VERSION ""

NS_ :

BS_:

BU_: XXX

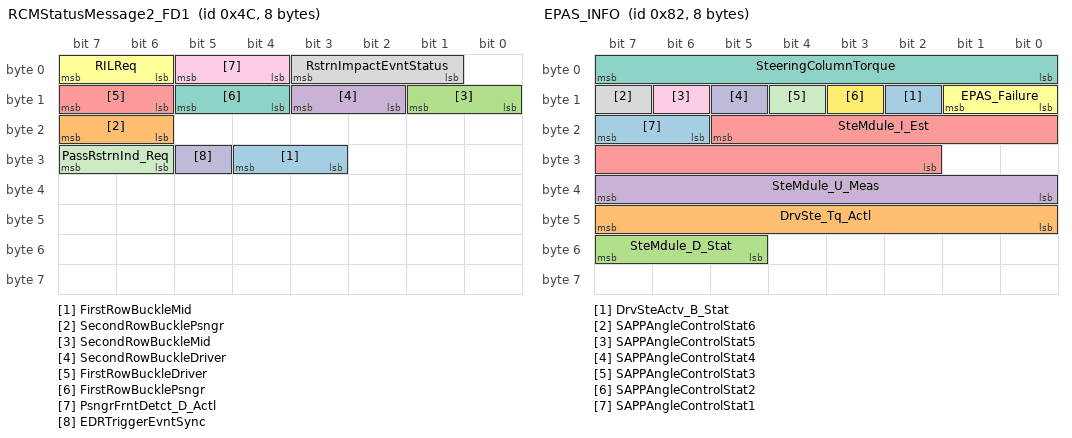
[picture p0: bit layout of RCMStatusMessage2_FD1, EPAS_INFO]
BO_ 76 RCMStatusMessage2_FD1: 8 GWM
 SG_ FirstRowBuckleMid : 28|2@0+ (1,0) [0|3] "SED"  IPMA_ADAS
 SG_ SecondRowBucklePsngr : 23|2@0+ (1,0) [0|3] "SED" Vector__XXX
 SG_ SecondRowBuckleMid : 9|2@0+ (1,0) [0|3] "SED" Vector__XXX
 SG_ SecondRowBuckleDriver : 11|2@0+ (1,0) [0|3] "SED" Vector__XXX
 SG_ FirstRowBuckleDriver : 15|2@0+ (1,0) [0|3] "SED"  CMR_DSMC,ABS_ESC,IPMA_ADAS,ECM_Diesel,PCM,PCM_HEV,TCM_DSL
 SG_ RILReq : 7|2@0+ (1,0) [0|3] "SED" Vector__XXX
 SG_ FirstRowBucklePsngr : 13|2@0+ (1,0) [0|3] "SED"  IPMA_ADAS
 SG_ RstrnImpactEvntStatus : 3|3@0+ (1,0) [0|7] "SED"  CMR_DSMC,SOBDMC_HPCM_FD1,ABS_ESC,IPMA_ADAS,ECM_Diesel,PCM,PCM_HEV,TCM_DSL
 SG_ PsngrFrntDetct_D_Actl : 5|2@0+ (1,0) [0|3] "SED" Vector__XXX
 SG_ EDRTriggerEvntSync : 29|1@0+ (1,0) [0|1] "SED"  IPMA_ADAS
 SG_ PassRstrnInd_Req : 31|2@0+ (1,0) [0|3] "SED" Vector__XXX

BO_ 130 EPAS_INFO: 8 PSCM
 SG_ DrvSteActv_B_Stat : 10|1@0+ (1,0) [0|1] "SED"  GWM,ABS_ESC
 SG_ DrvSte_Tq_Actl : 47|8@0+ (0.0625,-8) [-8|7.8125] "Nm"  GWM,ABS_ESC
 SG_ SteMdule_D_Stat : 55|3@0+ (1,0) [0|7] "SED"  GWM
 SG_ SteMdule_U_Meas : 39|8@0+ (0.05,6) [6|18.7] "Volts"  GWM
 SG_ SteMdule_I_Est : 21|12@0+ (0.05,-64) [-64|140.7] "Amps"  GWM
 SG_ EPAS_Failure : 9|2@0+ (1,0) [0|3] "SED"  IPMA_ADAS,GWM
 SG_ SteeringColumnTorque : 7|8@0+ (0.0625,-8) [-8|7.8125] "Nm"  GWM,IPMA_ADAS,ABS_ESC
 SG_ SAPPAngleControlStat6 : 15|1@0+ (1,0) [0|1] "SED"  GWM,IPMA_ADAS
 SG_ SAPPAngleControlStat5 : 14|1@0+ (1,0) [0|1] "SED"  GWM,IPMA_ADAS
 SG_ SAPPAngleControlStat4 : 13|1@0+ (1,0) [0|1] "SED"  GWM,IPMA_ADAS
 SG_ SAPPAngleControlStat3 : 12|1@0+ (1,0) [0|1] "SED"  GWM,IPMA_ADAS
 SG_ SAPPAngleControlStat2 : 11|1@0+ (1,0) [0|1] "SED"  GWM,IPMA_ADAS
 SG_ SAPPAngleControlStat1 : 23|2@0+ (1,0) [0|3] "SED"  GWM,IPMA_ADAS

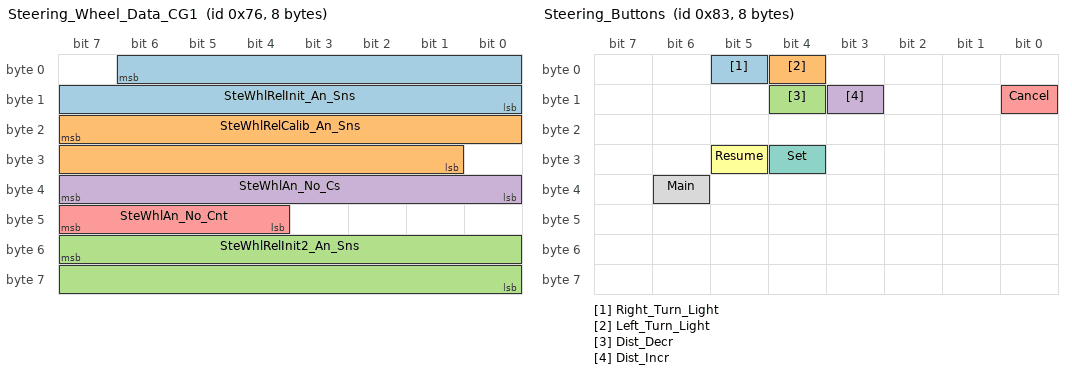
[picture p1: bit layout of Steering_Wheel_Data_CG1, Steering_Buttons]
BO_ 118 Steering_Wheel_Data_CG1: 8 XXX
 SG_ SteWhlRelInit_An_Sns : 6|15@0+ (0.1,-1600.0) [0|0] "deg" XXX
 SG_ SteWhlRelCalib_An_Sns : 23|15@0+ (0.1,-1600.0) [0|0] "deg" XXX
 SG_ SteWhlRelInit2_An_Sns : 55|16@0+ (0.1,-3200.0) [0|0] "deg" XXX
 SG_ SteWhlAn_No_Cs : 39|8@0+ (1,0) [0|0] "" XXX
 SG_ SteWhlAn_No_Cnt : 47|4@0+ (1,0) [0|0] "Counts" XXX

BO_ 131 Steering_Buttons: 8 XXX
 SG_ Right_Turn_Light : 5|1@0+ (1,0) [0|0] "" XXX
 SG_ Left_Turn_Light : 4|1@0+ (1,0) [0|0] "" XXX
 SG_ Dist_Decr : 12|1@0+ (1,0) [0|0] "" XXX
 SG_ Dist_Incr : 11|1@0+ (1,0) [0|0] "" XXX
 SG_ Cancel : 8|1@0+ (1,0) [0|0] "" XXX
 SG_ Resume : 29|1@0+ (1,0) [0|0] "" XXX
 SG_ Set : 28|1@0+ (1,0) [0|0] "" XXX
 SG_ Main : 38|1@0+ (1,0) [0|0] "" XXX

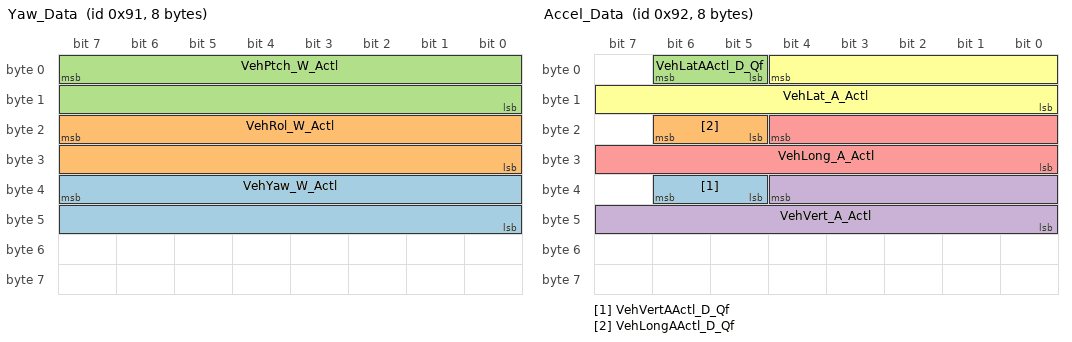
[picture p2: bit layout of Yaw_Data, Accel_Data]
BO_ 145 Yaw_Data: 8 XXX
 SG_ VehYaw_W_Actl : 39|16@0+ (0.0002,-6.5) [0|0] "rad/s" XXX
 SG_ VehRol_W_Actl : 23|16@0+ (0.0002,-6.5) [0|0] "rad/s" XXX
 SG_ VehPtch_W_Actl : 7|16@0+ (0.0002,-6.5) [0|0] "rad/s" XXX

BO_ 146 Accel_Data: 8 XXX
 SG_ VehVertAActl_D_Qf : 38|2@0+ (1,0) [0|0] "" XXX
 SG_ VehLongAActl_D_Qf : 22|2@0+ (1,0) [0|0] "" XXX
 SG_ VehLatAActl_D_Qf : 6|2@0+ (1,0) [0|0] "" XXX
 SG_ VehVert_A_Actl : 36|13@0+ (0.01,-40.0) [0|0] "m/s^2" XXX
 SG_ VehLong_A_Actl : 20|13@0+ (0.01,-40.0) [0|0] "m/s^2" XXX
 SG_ VehLat_A_Actl : 4|13@0+ (0.01,-40.0) [0|0] "m/s^2" XXX

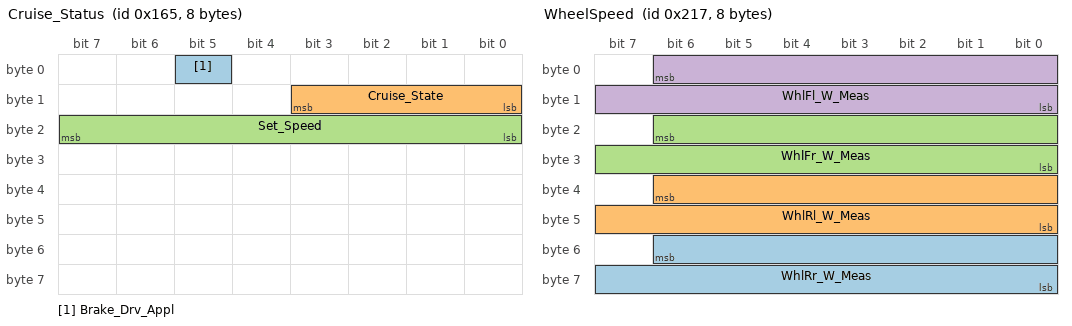
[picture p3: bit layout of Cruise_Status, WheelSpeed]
BO_ 357 Cruise_Status: 8 XXX
 SG_ Brake_Drv_Appl : 5|1@0+ (1,0) [0|0] "" XXX
 SG_ Cruise_State : 11|4@0+ (1,0) [0|0] "" XXX
 SG_ Set_Speed : 23|8@0+ (1,0) [0|0] "" XXX

BO_ 516 EngineData_14: 8 XXX
 SG_ ApedPosScal_Pc_Actl : 1|10@0+ (0.1,0) [0|0] "%" XXX

BO_ 535 WheelSpeed: 8 ABS_ESC
 SG_ WhlRr_W_Meas : 54|15@0+ (0.01,0) [0|327.65] "rad/s"  VDM,IPMA_ADAS,GWM,ECM_Diesel,PCM,PCM_HEV,PSCM,TCCM,TCM_DSL
 SG_ WhlRl_W_Meas : 38|15@0+ (0.01,0) [0|327.65] "rad/s"  VDM,IPMA_ADAS,GWM,ECM_Diesel,PCM,PCM_HEV,PSCM,TCCM,TCM_DSL
 SG_ WhlFr_W_Meas : 22|15@0+ (0.01,0) [0|327.65] "rad/s"  VDM,IPMA_ADAS,GWM,ECM_Diesel,PCM,PCM_HEV,PSCM,TCCM,TCM_DSL
 SG_ WhlFl_W_Meas : 6|15@0+ (0.01,0) [0|327.65] "rad/s"  VDM,IPMA_ADAS,GWM,ECM_Diesel,PCM,PCM_HEV,PSCM,TCCM,TCM_DSL

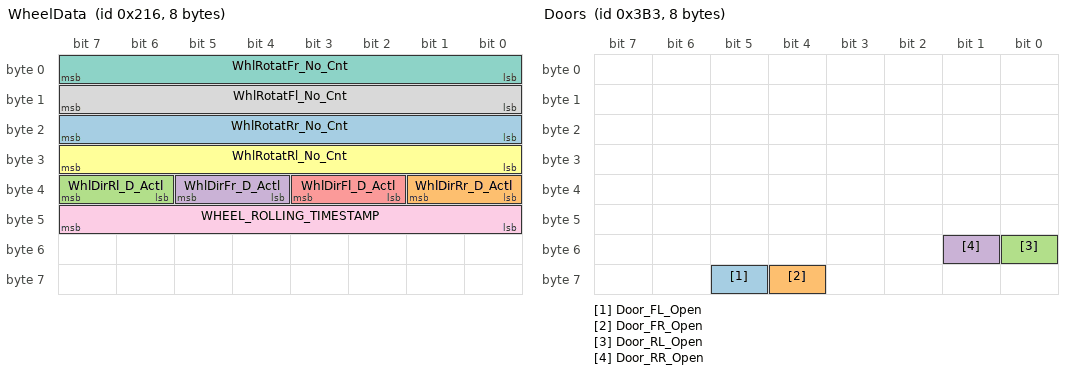
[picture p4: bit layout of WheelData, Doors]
BO_ 534 WheelData: 8 XXX
 SG_ WhlRotatRr_No_Cnt : 23|8@0+ (1,0) [0|0] "" XXX
 SG_ WhlDirRr_D_Actl : 33|2@0+ (1,0) [0|0] "" XXX
 SG_ WhlDirRl_D_Actl : 39|2@0+ (1,0) [0|0] "" XXX
 SG_ WhlDirFr_D_Actl : 37|2@0+ (1,0) [0|0] "" XXX
 SG_ WhlDirFl_D_Actl : 35|2@0+ (1,0) [0|0] "" XXX
 SG_ WhlRotatRl_No_Cnt : 31|8@0+ (1,0) [0|0] "" XXX
 SG_ WhlRotatFr_No_Cnt : 7|8@0+ (1,0) [0|0] "" XXX
 SG_ WhlRotatFl_No_Cnt : 15|8@0+ (1,0) [0|0] "" XXX
 SG_ WHEEL_ROLLING_TIMESTAMP : 47|8@0+ (1,0) [0|0] "" XXX

BO_ 947 Doors: 8 XXX
 SG_ Door_FL_Open : 61|1@0+ (1,0) [0|0] "" XXX
 SG_ Door_FR_Open : 60|1@0+ (1,0) [0|0] "" XXX
 SG_ Door_RL_Open : 48|1@0+ (1,0) [0|0] "" XXX
 SG_ Door_RR_Open : 49|1@0+ (1,0) [0|0] "" XXX

BO_ 963 BCM_to_HS_Body: 8 XXX
 SG_ Brake_Lights : 8|1@0+ (1,0) [0|0] "" XXX

BO_ 970 Lane_Keep_Assist_Control: 8 IPMA_ADAS
 SG_ Lkas_Action : 7|3@0+ (1,0) [0|7] "SED"  PSCM
 SG_ Lkas_Alert : 3|4@0+ (1,0) [0|15] "" XXX
 SG_ Lane_Curvature : 15|12@0+ (5E-006,-0.01024) [-0.01024|0.01023] "1/m"  PSCM
 SG_ Steer_Angle_Req : 19|12@0+ (0.05,-102.4) [-102.4|102.3] "mrad"  PSCM
 SG_ LkaDrvOvrrd_D_Rq : 38|2@0+ (1,0) [0|3] "SED"  PSCM
 SG_ LdwActvStats_D_Req : 4|3@0+ (1,0) [0|7] "SED"  PSCM
 SG_ LdwActvIntns_D_Req : 1|2@0+ (1,0) [0|3] "SED"  PSCM
 SG_ LaRampType_B_Req : 39|1@0+ (1,0) [0|1] "SED"  PSCM

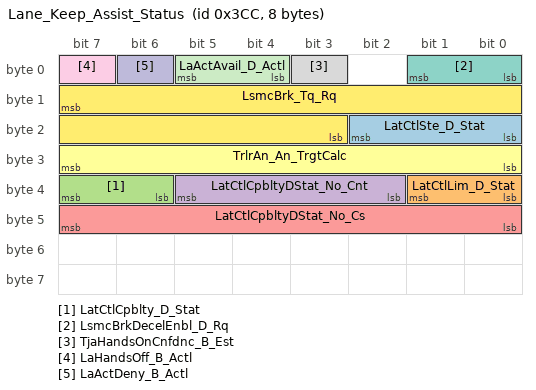
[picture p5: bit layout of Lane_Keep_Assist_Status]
BO_ 972 Lane_Keep_Assist_Status: 8 PSCM
 SG_ LatCtlSte_D_Stat : 18|3@0+ (1,0) [0|7] "SED"  IPMA_ADAS,GWM
 SG_ LatCtlLim_D_Stat : 33|2@0+ (1,0) [0|3] "SED"  IPMA_ADAS,GWM
 SG_ LatCtlCpblty_D_Stat : 39|2@0+ (1,0) [0|3] "SED"  IPMA_ADAS,GWM
 SG_ LatCtlCpbltyDStat_No_Cnt : 37|4@0+ (1,0) [0|15] "Unitless"  IPMA_ADAS,GWM
 SG_ LatCtlCpbltyDStat_No_Cs : 47|8@0+ (1,0) [0|255] "Unitless"  IPMA_ADAS,GWM
 SG_ TrlrAn_An_TrgtCalc : 31|8@0+ (1,-128) [-128|127] "degrees"  IPMA_ADAS
 SG_ LsmcBrkDecelEnbl_D_Rq : 1|2@0+ (1,0) [0|3] "SED"  ABS_ESC
 SG_ TjaHandsOnCnfdnc_B_Est : 3|1@0+ (1,0) [0|1] "SED"  IPMA_ADAS
 SG_ LaHandsOff_B_Actl : 7|1@0+ (1,0) [0|1] "SED"  IPMA_ADAS,GWM
 SG_ LaActDeny_B_Actl : 6|1@0+ (1,0) [0|1] "SED"  IPMA_ADAS,GWM
 SG_ LaActAvail_D_Actl : 5|2@0+ (1,0) [0|3] "SED"  IPMA_ADAS,GWM
 SG_ LsmcBrk_Tq_Rq : 15|13@0+ (4,0) [0|32764] "Nm"  ABS_ESC

BO_ 984 Lane_Keep_Assist_Ui: 8 IPMA_ADAS
 SG_ FeatConfigIpmaActl : 7|16@0+ (1,0) [0|65535] "Undefined"  GWM
 SG_ FeatNoIpmaActl : 23|16@0+ (1,0) [0|65535] "Number"  GWM
 SG_ PersIndexIpma_D_Actl : 39|3@0+ (1,0) [0|7] "SED"  GWM
 SG_ AhbcRampingV_D_Rq : 57|2@0+ (1,0) [0|3] "SED"  GWM
 SG_ Lines_Hud : 55|5@0+ (1,0) [0|31] "SED"  GWM
 SG_ LaDenyStats_B_Dsply : 32|1@0+ (1,0) [0|1] "SED"  GWM
 SG_ Hands_Warning_W_Chime : 50|2@0+ (1,0) [0|3] "SED"  GWM
 SG_ CamraDefog_B_Req : 36|1@0+ (1,0) [0|1] "SED"  GWM
 SG_ CamraStats_D_Dsply : 35|2@0+ (1,0) [0|3] "SED"  GWM
 SG_ DasAlrtLvl_D_Dsply : 42|3@0+ (1,0) [0|7] "SED"  GWM
 SG_ DasStats_D_Dsply : 47|2@0+ (1,0) [0|3] "SED"  GWM
 SG_ DasWarn_D_Dsply : 44|2@0+ (1,0) [0|3] "SED"  GWM
 SG_ AhbHiBeam_D_Rq : 59|2@0+ (1,0) [0|3] "SED"  GWM
 SG_ Hands_Warning : 49|1@0+ (1,0) [0|1] "SED"  GWM
 SG_ Set_Me_X30 : 63|8@0+ (1,0) [0|255] "SED"  GWM

CM_ SG_ 970 Lkas_Action "only vals 4, 5, 8, 9 seem to work. 4 and 5 are a bit smoother" ;

VAL_ 76 FirstRowBuckleMid 3 "Unknown" 2 "Unbelted" 1 "Belted" 0 "Faulty" ;
VAL_ 76 SecondRowBucklePsngr 3 "Unknown" 2 "Unbelted" 1 "Belted" 0 "Faulty" ;
VAL_ 76 SecondRowBuckleMid 3 "Unknown" 2 "Unbelted" 1 "Belted" 0 "Faulty" ;
VAL_ 76 SecondRowBuckleDriver 3 "Unknown" 2 "Unbelted" 1 "Belted" 0 "Faulty" ;
VAL_ 76 FirstRowBuckleDriver 3 "Unknown" 2 "Unbelted" 1 "Belted" 0 "Faulty" ;
VAL_ 76 RILReq 3 "Not_Used" 2 "Plant_Mode" 1 "On" 0 "Off" ;
VAL_ 76 FirstRowBucklePsngr 3 "Unknown" 2 "Unbelted" 1 "Belted" 0 "Faulty" ;
VAL_ 76 RstrnImpactEvntStatus 7 "Invalid" 6 "Not_Used_4" 5 "Threshold_2_Exceeded" 4 "Not_Used_3" 3 "Threshold_1_Exceeded" 2 "Not_Used_2" 1 "Not_Used_1" 0 "Normal" ;
VAL_ 76 PsngrFrntDetct_D_Actl 3 "Unknown" 2 "Empty" 0 "Faulty" 1 "Occupied" ;
VAL_ 76 EDRTriggerEvntSync 1 "Threshold_Exceeded" 0 "Normal" ;
VAL_ 76 PassRstrnInd_Req 3 "ABOnNotIllum_OffNotIllum" 2 "AirbagOnNot_Illum_OffIllum" 1 "AirbagOn_Illum_OffNotIllum" 0 "AirbagOn_Illum_Off_Illum" ;
VAL_ 130 TrlrHitchLamp_D_Rqst 1 "On" 0 "Off" ;
VAL_ 130 VehVTrlrAid_B_Rq 1 "Request" 0 "NoRequest" ;
VAL_ 130 DrvSteActv_B_Stat 1 "Active" 0 "Inactive" ;
VAL_ 130 DrvSte_Tq_Actl 255 "Invalid" 254 "Unknown" ;
VAL_ 130 SteMdule_D_Stat 7 "NotUsed" 6 "EPAS_Failure3" 5 "EPAS_Failure2" 4 "System_Failure" 3 "EPAS_Shutdown" 2 "Normal_Op_Full_Assist" 1 "Normal_Op_Limited_Assist" 0 "EPAS_Initialization" ;
VAL_ 130 SteMdule_U_Meas 255 "Invalid" ;
VAL_ 130 SteMdule_I_Est 4095 "Invalid" ;
VAL_ 130 EPAS_Failure 3 "SERVICE_POWER_STEERING_NOW" 2 "SERVICE_POWER_STEERING" 1 "POWER_STRG_ASSIST_FAULT" 0 "EPAS_OK_NO_MESSAGE" ;
VAL_ 130 SteeringColumnTorque 255 "Invalid" 254 "Unknown" ;
VAL_ 130 SAPPAngleControlStat6 1 "RequestedAngleNotReached" 0 "RequestedAngleCanBeReached" ;
VAL_ 130 SAPPAngleControlStat5 1 "StrgColTorqueExceed_EAROn" 0 "ExternalSigContentOKforEAC" ;
VAL_ 130 SAPPAngleControlStat4 1 "SpeedLimitExceededEAROn" 0 "ExternalSigContentOKforEAC" ;
VAL_ 130 SAPPAngleControlStat3 1 "EARactiveNoReverseEngage" 0 "ExternalSigContentOKforEAC" ;
VAL_ 130 SAPPAngleControlStat2 1 "Rel_ExtSteeringAngleReqx" 0 "NoRel_ExtSteeringAngleReqx" ;
VAL_ 130 SAPPAngleControlStat1 3 "Fault" 2 "Active" 1 "Open" 0 "Closed" ;
VAL_ 357 Cruise_State 4 "active" 3 "standby" 0 "off" ;
VAL_ 970 LkaDrvOvrrd_D_Rq 3 "Level_3" 2 "Level_2" 1 "Level_1" 0 "Level_0" ;
VAL_ 970 Lkas_Action 7 "NotUsed" 6 "LkaIncrIntervRight" 5 "LkaSupprRight" 4 "LkaStandIntervRight" 3 "LkaSupprLeft" 2 "LkaStandIntervLeft" 1 "LkaIncrIntervLeft" 0 "LkaNoInterv" ;
CM_ VAL_ 970 Lkas_Alert 15 "no_alert" 3 "high_intensity" 2 "mid_intensity" 1 "low_intensity" ;
VAL_ 970 Steer_angle_Req 4095 "Fault" ;
VAL_ 970 LaRampType_B_Req 1 "Quick" 0 "Smooth" ;
VAL_ 970 Lkas_Curvature 4095 "Fault" ;
VAL_ 970 LdwActvStats_D_Req 7 "LDW_Suppress_Right_Left" 6 "Not_Used2" 5 "LDW_Suppress_Right" 4 "LDW_Warning_Right" 3 "LDW_Suppress_Left" 2 "LDW_Warning_Left" 1 "LDW_DemoVibration" 0 "LDW_Idle" ;
VAL_ 970 LdwActvIntns_D_Req 3 "High" 2 "Medium" 1 "Low" 0 "None" ;
VAL_ 970 Lkas_Alert 15 "no_alert" 3 "high_intensity" 2 "mid_intensity" 1 "low_intensity" ;
VAL_ 972 LatCtlSte_D_Stat 7 "NotUsed3" 6 "NotUsed2" 5 "NotUsed1" 4 "Denied" 3 "RampOut" 2 "ContLatControlInProgress" 1 "Available" 0 "Unavailable" ;
VAL_ 972 LatCtlLim_D_Stat 3 "LimitWithDriverActive" 2 "LimitReached" 1 "LimitClose" 0 "LimitNotReached" ;
VAL_ 972 LatCtlCpblty_D_Stat 3 "Faulty" 2 "ExtendedModeAvailable" 1 "LimitedModeAvailable" 0 "NoModeAvailable" ;
VAL_ 972 LsmcBrkDecelEnbl_D_Rq 3 "NotUsed2" 2 "NotUsed1" 1 "On" 0 "Off" ;
VAL_ 972 TjaHandsOnCnfdnc_B_Est 1 "High_Confidence" 0 "Low_Confidence" ;
VAL_ 972 LaHandsOff_B_Actl 1 "Hands_Off" 0 "Hands_On" ;
VAL_ 972 LaActDeny_B_Actl 1 "LA_Denied" 0 "LA_Not_Denied" ;
VAL_ 972 LaActAvail_D_Actl 3 "LKA_LCA_LDW_Avail" 2 "LCA_LKA_Avail_LDW_Suppress" 1 "LCA_LKA_Suppress_LDW_Avail" 0
VAL_ 984 PersIndexIpma_D_Actl 7 "Unused_3" 6 "Unused_2" 5 "Unused_1" 4 "Vehicle" 3 "PERS_4" 2 "PERS_3" 1 "PERS_2" 0 "PERS_1" ;
VAL_ 984 AhbcRampingV_D_Rq 3 "Slow" 2 "Medium" 1 "Fast" 0 "Immediately" ;
VAL_ 984 Lines_Hud 31 "Unused7" 30 "LA_Off" 29 "Unused5" 28 "Unused4" 27 "Unused3" 26 "Unused2" 25 "Unused1" 24 "InerveneLeft_InterveneRght" 23 "WarnLeft_InterveneRight" 22 "SuppressLeft_InterveneRght" 21 "AvailLeft_InterveneRhtt" 20 "NoLeft_InterveneRight" 19 "InterveneLeft_WarnRight" 18 "WarnLeft_WarnRight" 17 "SuppressLeft_WarnRight" 16 "AvailableLeft_WarnRight" 15 "NoLeft_WarnRight" 14 "InterveneLeft_SuppressRght" 13 "WarnLeft_SuppressRight" 12 "SuppressLeft_SuppressRight" 11 "AvailLeft_SuppressRight" 10 "NoLeft_SuppressRight" 9 "InterveneLeft_AvailRight" 8 "WarnLeft_AvailRight" 7 "SuppressLeft_AvailRight" 6 "AvailableLeft_AvailRight" 5 "NoLeft_AvailableRight" 4 "InterveneLeft_NoRight" 3 "WarnLeft_NoRight" 2 "SuppressLeft_NoRight" 1 "AvailableLeft_NoRight" 0 "NoLeft_NoRight" ;
VAL_ 984 LaDenyStats_B_Dsply 1 "Unavailable" 0 "Available" ;
VAL_ 984 Hands_Warning_W_Chime 3 "Suppressed" 2 "Level2" 1 "Level1" 0 "HandsOn" ;
VAL_ 984 CamraDefog_B_Req 1 "On" 0 "Off" ;
VAL_ 984 CamraStats_D_Dsply 3 "FrtCam_TempUnavailOther" 2 "FrtCam_TempUnavailVisibile" 1 "Front_Camera_Service_Reqd" 0 "Front_Camera_OK" ;
VAL_ 984 DasAlrtLvl_D_Dsply 5 "Alertness_Level_5" 4 "Alertness_Level_4" 3 "Alertness_Level_3" 2 "Alertness_Level_2" 1 "Alertness_Level_1" 0 "Undefined" ;
VAL_ 984 DasStats_D_Dsply 3 "Available" 2 "Unavailable_Other" 1 "Feedback_due_to_Speed" 0 "Off" ;
VAL_ 984 DasWarn_D_Dsply 3 "Undefined" 2 "Warning_Level_2" 1 "Warning_Level_1" 0 "No_Warning" ;
VAL_ 984 AhbHiBeam_D_Rq 3 "NotUsed" 2 "HighBeamRecommended" 1 "LowBeamRecommended" 0 "DeactivatedUnavailable" ; "LCA_LKA_LDW_Suppress" ;
